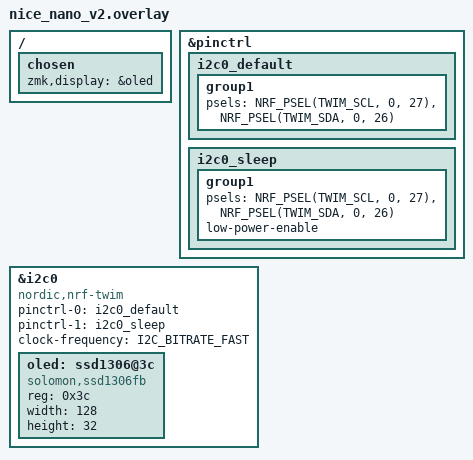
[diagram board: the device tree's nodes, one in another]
/*
 * Copyright (c) 2024 The ZMK Contributors
 *
 * SPDX-License-Identifier: MIT
 */

/ {
    chosen {
        zmk,display = &oled;
    };
};

&pinctrl {
    i2c0_default: i2c0_default {
        group1 {
            psels = <NRF_PSEL(TWIM_SCL, 0, 27)>, <NRF_PSEL(TWIM_SDA, 0, 26)>;
        };
    };

    i2c0_sleep: i2c0_sleep {
        group1 {
            psels = <NRF_PSEL(TWIM_SCL, 0, 27)>, <NRF_PSEL(TWIM_SDA, 0, 26)>;
            low-power-enable;
        };
    };
};

&i2c0 {
    compatible = "nordic,nrf-twim";
    status = "okay";

    pinctrl-0 = <&i2c0_default>;
    pinctrl-1 = <&i2c0_sleep>;
    pinctrl-names = "default", "sleep";

    clock-frequency = <I2C_BITRATE_FAST>;

    oled: ssd1306@3c {
        compatible = "solomon,ssd1306fb";
        reg = <0x3c>;     /* Most 0.91" OLEDs use 0x3C */
        width = <128>;
        height = <32>;
    };
};
